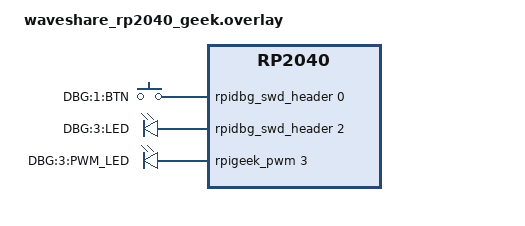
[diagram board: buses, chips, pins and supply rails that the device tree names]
/*
 * SPDX-FileCopyrightText: Copyright (c) 2023-2026 TiaC Systems
 * SPDX-License-Identifier: Apache-2.0
 */

#include <zephyr/dt-bindings/input/input-event-codes.h>
#include <zephyr/dt-bindings/gpio/gpio.h>
#include <zephyr/dt-bindings/pwm/pwm.h>

/ {
	aliases {
		/delete-property/ sw0;
		sw0 = &rpigeek_dbg_btn;
		/delete-property/ led0;
		led0 = &rpigeek_dbg_led;
		/delete-property/ pwm-led0;
		pwm-led0 = &rpigeek_dbg_pwm_led;
	};

	/delete-node/ gpio_keys;
	/delete-node/ gpio-keys;
	gpio_keys: rpigeek-dbg-btns {
		compatible = "gpio-keys";
		rpigeek_dbg_btn: rpigeek-dbg-btn {
			label = "DBG:1:BTN";
			zephyr,code = <INPUT_KEY_0>;
			gpios = <&rpidbg_swd_header 0 (GPIO_PULL_DOWN | GPIO_ACTIVE_HIGH)>;
		};
	};

	/delete-node/ gpio_leds;
	/delete-node/ gpio-leds;
	gpio_leds: rpigeek-dbg-leds {
		compatible = "gpio-leds";
		rpigeek_dbg_led: rpigeek-dbg-led {
			label = "DBG:3:LED";
			gpios = <&rpidbg_swd_header 2 (GPIO_ACTIVE_HIGH)>;
		};
	};

	/delete-node/ pwm_leds;
	/delete-node/ pwm-leds;
	pwm_leds: rpigeek-dbg-pwm-leds {
		compatible = "pwm-leds";
		rpigeek_dbg_pwm_led: rpigeek-dbg-pwm-led {
			label = "DBG:3:PWM_LED";
			pwms = <&rpigeek_pwm 3 PWM_MSEC(20) (PWM_POLARITY_NORMAL)>;
		};
	};
};

&rpigeek_pwm {
	divider-int-1 = <255>;	/* led: PWM1CHB (3) */
};
